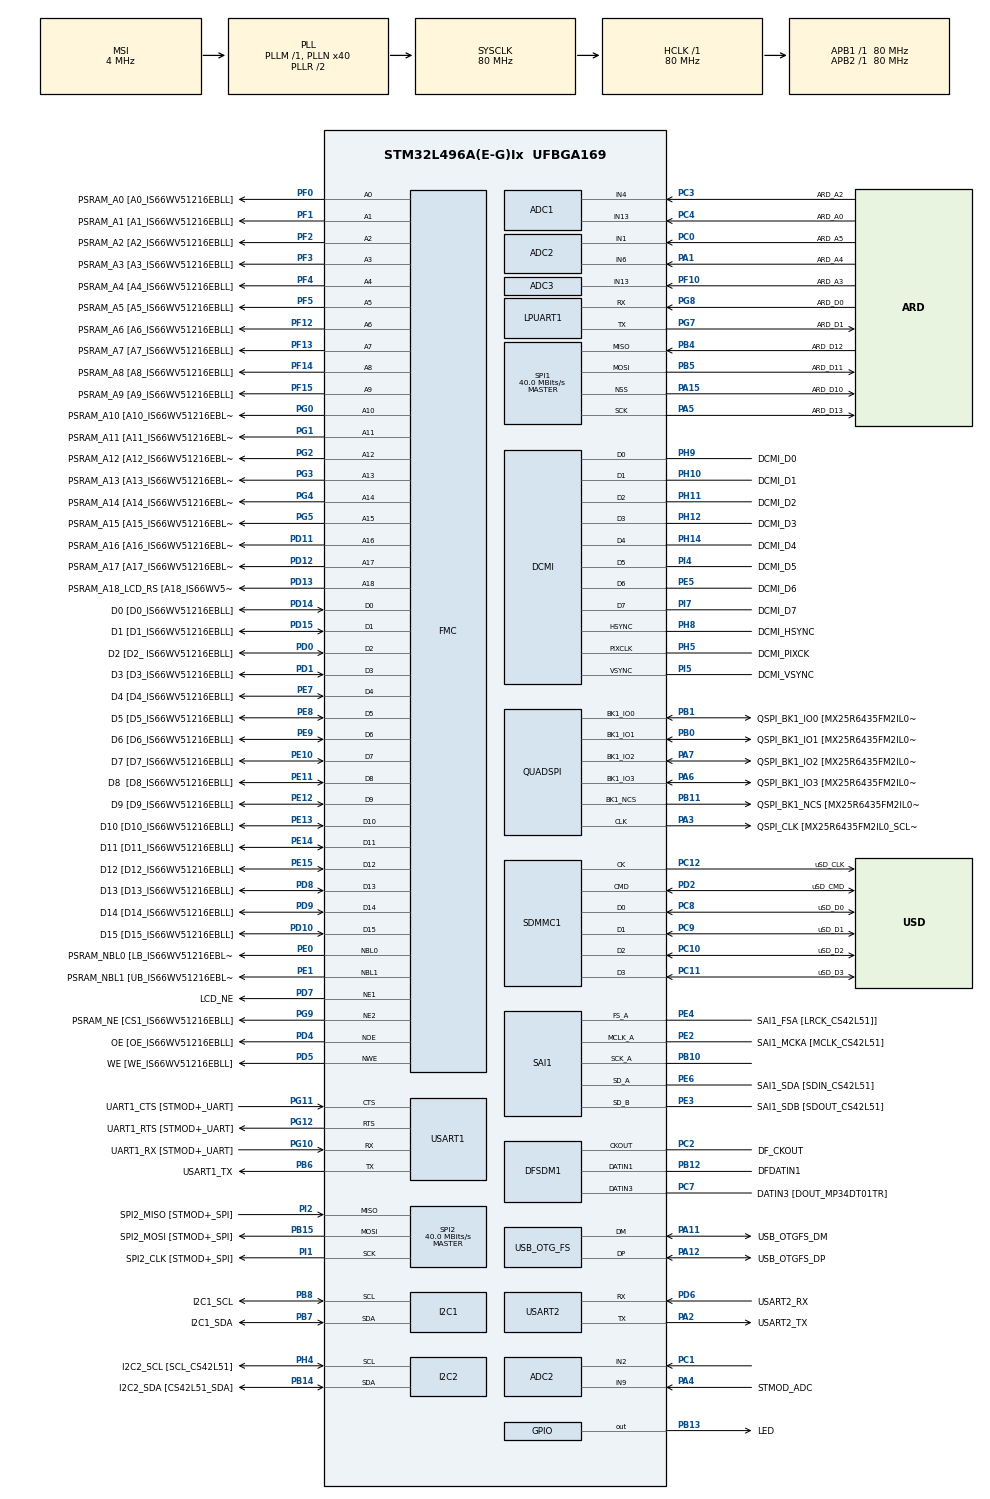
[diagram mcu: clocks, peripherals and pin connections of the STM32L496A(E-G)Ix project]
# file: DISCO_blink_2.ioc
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ADC1.Channel-0\#ChannelRegularConversion=ADC_CHANNEL_4
ADC1.ClockPrescaler=ADC_CLOCK_ASYNC_DIV4
ADC1.NbrOfConversionFlag=1
ADC1.OffsetNumber-0\#ChannelRegularConversion=ADC_OFFSET_NONE
ADC1.Rank-0\#ChannelRegularConversion=1
ADC1.SamplingTime-0\#ChannelRegularConversion=ADC_SAMPLETIME_2CYCLES_5
ADC1.master=1
ADC2.Channel-0\#ChannelRegularConversion=ADC_CHANNEL_9
ADC2.ClockPrescaler=ADC_CLOCK_ASYNC_DIV4
ADC2.NbrOfConversionFlag=1
ADC2.OffsetNumber-0\#ChannelRegularConversion=ADC_OFFSET_NONE
ADC2.Rank-0\#ChannelRegularConversion=1
ADC2.SamplingTime-0\#ChannelRegularConversion=ADC_SAMPLETIME_2CYCLES_5
ADC3.Channel-0\#ChannelRegularConversion=ADC_CHANNEL_13
ADC3.ClockPrescaler=ADC_CLOCK_ASYNC_DIV4
ADC3.NbrOfConversionFlag=1
ADC3.OffsetNumber-0\#ChannelRegularConversion=ADC_OFFSET_NONE
ADC3.Rank-0\#ChannelRegularConversion=1
ADC3.SamplingTime-0\#ChannelRegularConversion=ADC_SAMPLETIME_2CYCLES_5
DCMI.JPEGMode=DCMI_JPEG_DISABLE
I2C1.Timing=0x10D19CE4
I2C2.Timing=0x10D19CE4
Mcu.Family=STM32L4
Mcu.Name=STM32L496A(E-G)Ix
Mcu.Package=UFBGA169
NVIC.OTG_FS_IRQn=true\:0\:0\:false\:false\:true\:true\:true\:true
NVIC.PriorityGroup=NVIC_PRIORITYGROUP_4
PA0.GPIO_Label=STMOD_PWM
PA0.Mode=SYS_WakeUp0
PA0.Signal=SYS_WKUP1
PA1.GPIO_Label=ARD_A4
PA1.Signal=ADCx_IN6
PA10.GPIO_Label=USB_OTGFS_ID
PA10.Signal=USB_OTG_FS_ID
PA11.GPIO_Label=USB_OTGFS_DM
PA11.Mode=Device_Only
PA11.Signal=USB_OTG_FS_DM
PA12.GPIO_Label=USB_OTGFS_DP
PA12.Mode=Device_Only
PA12.Signal=USB_OTG_FS_DP
PA13\ (JTMS/SWDIO).GPIO_Label=SWDIO
PA13\ (JTMS/SWDIO).Mode=Serial_Wire
PA13\ (JTMS/SWDIO).Signal=SYS_JTMS-SWDIO
PA14\ (JTCK/SWCLK).GPIO_Label=SWCLK
PA14\ (JTCK/SWCLK).Mode=Serial_Wire
PA14\ (JTCK/SWCLK).Signal=SYS_JTCK-SWCLK
PA15\ (JTDI).GPIO_Label=ARD_D10
PA15\ (JTDI).Mode=NSS_Signal_Hard_Output
PA15\ (JTDI).Signal=SPI1_NSS
PA2.GPIO_Label=USART2_TX
PA2.Mode=Asynchronous
PA2.Signal=USART2_TX
PA3.GPIO_Label=QSPI_CLK [MX25R6435FM2IL0_SCLK]
PA3.Mode=Single Bank 1
PA3.Signal=QUADSPI_CLK
PA4.GPIO_Label=STMOD_ADC
PA4.Signal=ADCx_IN9
PA5.GPIO_Label=ARD_D13
PA5.Mode=Full_Duplex_Master
PA5.Signal=SPI1_SCK
PA6.GPIO_Label=QSPI_BK1_IO3 [MX25R6435FM2IL0_SIO3]
PA6.Mode=Single Bank 1
PA6.Signal=QUADSPI_BK1_IO3
PA7.GPIO_Label=QSPI_BK1_IO2 [MX25R6435FM2IL0_SIO2]
PA7.Mode=Single Bank 1
PA7.Signal=QUADSPI_BK1_IO2
PA8.GPIO_Label=DCMI_CLK
PA8.Signal=LPTIM2_OUT
PA9.GPIO_Label=USB_OTGFS_VBUS
PA9.Signal=USB_OTG_FS_VBUS
PB0.GPIO_Label=QSPI_BK1_IO1 [MX25R6435FM2IL0_SIO1]
PB0.Mode=Single Bank 1
PB0.Signal=QUADSPI_BK1_IO1
PB1.GPIO_Label=QSPI_BK1_IO0 [MX25R6435FM2IL0_SIO0]
PB1.Mode=Single Bank 1
PB1.Signal=QUADSPI_BK1_IO0
PB10.Mode=SAI_A_MasterWithClock
PB10.Signal=SAI1_SCK_A
PB11.GPIO_Label=QSPI_BK1_NCS [MX25R6435FM2IL0_CS]
PB11.Mode=Single Bank 1
PB11.Signal=QUADSPI_BK1_NCS
PB12.GPIO_Label=DFDATIN1
PB12.Signal=S_DATAIN1DFSDM1
PB13.GPIO_Label=LED
PB13.GPIO_ModeDefaultOutputPP=GPIO_MODE_OUTPUT_OD
PB13.GPIO_PuPd=GPIO_NOPULL
PB13.Signal=GPIO_Output
PB14.GPIO_Label=I2C2_SDA [CS42L51_SDA]
PB14.GPIO_Pu=GPIO_PULLUP
PB14.Mode=I2C
PB14.Signal=I2C2_SDA
PB15.GPIO_Label=SPI2_MOSI [STMOD+_SPI]
PB15.Mode=Full_Duplex_Master
PB15.Signal=SPI2_MOSI
PB3\ (JTDO/TRACESWO).GPIO_Label=SWO
PB3\ (JTDO/TRACESWO).Signal=SYS_JTDO-SWO
PB4\ (NJTRST).GPIO_Label=ARD_D12
PB4\ (NJTRST).Mode=Full_Duplex_Master
PB4\ (NJTRST).Signal=SPI1_MISO
PB5.GPIO_Label=ARD_D11
PB5.Mode=Full_Duplex_Master
PB5.Signal=SPI1_MOSI
PB6.GPIO_Label=USART1_TX
PB6.Mode=Asynchronous
PB6.Signal=USART1_TX
PB7.GPIO_Label=I2C1_SDA
PB7.GPIO_Pu=GPIO_PULLUP
PB7.Mode=I2C
PB7.Signal=I2C1_SDA
PB8.GPIO_Label=I2C1_SCL
PB8.GPIO_Pu=GPIO_PULLUP
PB8.Mode=I2C
PB8.Signal=I2C1_SCL
PB9.GPIO_Label=ARD_D5
PB9.Signal=S_TIM4_CH4
PC0.GPIO_Label=ARD_A5
PC0.Signal=ADCx_IN1
PC1.Signal=ADCx_IN2
PC10.GPIO_Label=uSD_D2
PC10.Mode=SD_4_bits_Wide_bus
PC10.Signal=SDMMC1_D2
PC11.GPIO_Label=uSD_D3
PC11.Mode=SD_4_bits_Wide_bus
PC11.Signal=SDMMC1_D3
PC12.GPIO_Label=uSD_CLK
PC12.Mode=SD_4_bits_Wide_bus
PC12.Signal=SDMMC1_CK
PC13.GPIO_Label=JOY_SEL [Selection_MT008]
PC13.Mode=SYS_WakeUp1
PC13.Signal=SYS_WKUP2
PC14-OSC32_IN\ (PC14).Mode=LSE-External-Oscillator
PC14-OSC32_IN\ (PC14).Signal=RCC_OSC32_IN
PC15-OSC32_OUT\ (PC15).Mode=LSE-External-Oscillator
PC15-OSC32_OUT\ (PC15).Signal=RCC_OSC32_OUT
PC2.GPIO_Label=DF_CKOUT
PC2.Signal=S_CKOUTDFSDM1
PC3.GPIO_Label=ARD_A2
PC3.Signal=ADCx_IN4
PC4.GPIO_Label=ARD_A0
PC4.Signal=ADCx_IN13
PC7.GPIO_Label=DATIN3 [DOUT_MP34DT01TR]
PC7.Signal=S_DATAIN3DFSDM1
PC8.GPIO_Label=uSD_D0
PC8.Mode=SD_4_bits_Wide_bus
PC8.Signal=SDMMC1_D0
PC9.GPIO_Label=uSD_D1
PC9.Mode=SD_4_bits_Wide_bus
PC9.Signal=SDMMC1_D1
PD0.GPIO_Label=D2 [D2_ IS66WV51216EBLL]
PD0.Signal=FMC_D2_DA2
PD1.GPIO_Label=D3 [D3_IS66WV51216EBLL]
PD1.Signal=FMC_D3_DA3
PD10.GPIO_Label=D15 [D15_IS66WV51216EBLL]
PD10.Signal=FMC_D15_DA15
PD11.GPIO_Label=PSRAM_A16 [A16_IS66WV51216EBLL]
PD11.Signal=FMC_A16_CLE
PD12.GPIO_Label=PSRAM_A17 [A17_IS66WV51216EBLL]
PD12.Signal=FMC_A17_ALE
PD13.GPIO_Label=PSRAM_A18_LCD_RS [A18_IS66WV51216EBLL]
PD13.Signal=FMC_A18
PD14.GPIO_Label=D0 [D0_IS66WV51216EBLL]
PD14.Signal=FMC_D0_DA0
PD15.GPIO_Label=D1 [D1_IS66WV51216EBLL]
PD15.Signal=FMC_D1_DA1
PD2.GPIO_Label=uSD_CMD
PD2.Mode=SD_4_bits_Wide_bus
PD2.Signal=SDMMC1_CMD
PD4.GPIO_Label=OE [OE_IS66WV51216EBLL]
PD4.Signal=FMC_NOE
PD5.GPIO_Label=WE [WE_IS66WV51216EBLL]
PD5.Signal=FMC_NWE
PD6.GPIO_Label=USART2_RX
PD6.Mode=Asynchronous
PD6.Signal=USART2_RX
PD7.GPIO_Label=LCD_NE
PD7.Mode=NorPsramChipSelect1_2
PD7.Signal=FMC_NE1
PD8.GPIO_Label=D13 [D13_IS66WV51216EBLL]
PD8.Signal=FMC_D13_DA13
PD9.GPIO_Label=D14 [D14_IS66WV51216EBLL]
PD9.Signal=FMC_D14_DA14
PE0.GPIO_Label=PSRAM_NBL0 [LB_IS66WV51216EBLL]
PE0.Signal=FMC_NBL0
PE1.GPIO_Label=PSRAM_NBL1 [UB_IS66WV51216EBLL]
PE1.Signal=FMC_NBL1
PE10.GPIO_Label=D7 [D7_IS66WV51216EBLL]
PE10.Signal=FMC_D7_DA7
PE11.GPIO_Label=D8  [D8_IS66WV51216EBLL]
PE11.Signal=FMC_D8_DA8
PE12.GPIO_Label=D9 [D9_IS66WV51216EBLL]
PE12.Signal=FMC_D9_DA9
PE13.GPIO_Label=D10 [D10_IS66WV51216EBLL]
PE13.Signal=FMC_D10_DA10
PE14.GPIO_Label=D11 [D11_IS66WV51216EBLL]
PE14.Signal=FMC_D11_DA11
PE15.GPIO_Label=D12 [D12_IS66WV51216EBLL]
PE15.Signal=FMC_D12_DA12
PE2.GPIO_Label=SAI1_MCKA [MCLK_CS42L51]
PE2.Mode=SAI_A_MasterWithClock
PE2.Signal=SAI1_MCLK_A
PE3.GPIO_Label=SAI1_SDB [SDOUT_CS42L51]
PE3.Mode=SAI_B_SyncSlave
PE3.Signal=SAI1_SD_B
PE4.GPIO_Label=SAI1_FSA [LRCK_CS42L51]]
PE4.Mode=SAI_A_MasterWithClock
PE4.Signal=SAI1_FS_A
PE5.GPIO_Label=DCMI_D6
PE5.Mode=Slave_8_bits_External_Synchro
PE5.Signal=DCMI_D6
PE6.GPIO_Label=SAI1_SDA [SDIN_CS42L51]
PE6.Mode=SAI_A_MasterWithClock
PE6.Signal=SAI1_SD_A
PE7.GPIO_Label=D4 [D4_IS66WV51216EBLL]
PE7.Signal=FMC_D4_DA4
PE8.GPIO_Label=D5 [D5_IS66WV51216EBLL]
PE8.Signal=FMC_D5_DA5
PE9.GPIO_Label=D6 [D6_IS66WV51216EBLL]
PE9.Signal=FMC_D6_DA6
PF0.GPIO_Label=PSRAM_A0 [A0_IS66WV51216EBLL]
PF0.Signal=FMC_A0
PF1.GPIO_Label=PSRAM_A1 [A1_IS66WV51216EBLL]
PF1.Signal=FMC_A1
PF10.GPIO_Label=ARD_A3
PF10.Mode=IN13-Single-Ended
PF10.Signal=ADC3_IN13
PF12.GPIO_Label=PSRAM_A6 [A6_IS66WV51216EBLL]
PF12.Signal=FMC_A6
PF13.GPIO_Label=PSRAM_A7 [A7_IS66WV51216EBLL]
PF13.Signal=FMC_A7
PF14.GPIO_Label=PSRAM_A8 [A8_IS66WV51216EBLL]
PF14.Signal=FMC_A8
PF15.GPIO_Label=PSRAM_A9 [A9_IS66WV51216EBLL]
PF15.Signal=FMC_A9
PF2.GPIO_Label=PSRAM_A2 [A2_IS66WV51216EBLL]
PF2.Signal=FMC_A2
PF3.GPIO_Label=PSRAM_A3 [A3_IS66WV51216EBLL]
PF3.Signal=FMC_A3
PF4.GPIO_Label=PSRAM_A4 [A4_IS66WV51216EBLL]
PF4.Signal=FMC_A4
PF5.GPIO_Label=PSRAM_A5 [A5_IS66WV51216EBLL]
PF5.Signal=FMC_A5
PG0.GPIO_Label=PSRAM_A10 [A10_IS66WV51216EBLL]
PG0.Signal=FMC_A10
PG1.GPIO_Label=PSRAM_A11 [A11_IS66WV51216EBLL]
PG1.Signal=FMC_A11
PG10.GPIO_Label=UART1_RX [STMOD+_UART]
PG10.Mode=Asynchronous
PG10.Signal=USART1_RX
PG11.GPIO_Label=UART1_CTS [STMOD+_UART]
PG11.Mode=CTS_RTS
PG11.Signal=USART1_CTS
PG12.GPIO_Label=UART1_RTS [STMOD+_UART]
PG12.Mode=CTS_RTS
PG12.Signal=USART1_RTS
PG2.GPIO_Label=PSRAM_A12 [A12_IS66WV51216EBLL]
PG2.Signal=FMC_A12
PG3.GPIO_Label=PSRAM_A13 [A13_IS66WV51216EBLL]
PG3.Signal=FMC_A13
PG4.GPIO_Label=PSRAM_A14 [A14_IS66WV51216EBLL]
PG4.Signal=FMC_A14
PG5.GPIO_Label=PSRAM_A15 [A15_IS66WV51216EBLL]
PG5.Signal=FMC_A15
PG7.GPIO_Label=ARD_D1
PG7.Mode=Asynchronous
PG7.Signal=LPUART1_TX
PG8.GPIO_Label=ARD_D0
PG8.Mode=Asynchronous
PG8.Signal=LPUART1_RX
PG9.GPIO_Label=PSRAM_NE [CS1_IS66WV51216EBLL]
PG9.Mode=NorPsramChipSelect2_1
PG9.Signal=FMC_NE2
PH0-OSC_IN\ (PH0).Mode=HSE-External-Oscillator
PH0-OSC_IN\ (PH0).Signal=RCC_OSC_IN
PH1-OSC_OUT\ (PH1).Mode=HSE-External-Oscillator
PH1-OSC_OUT\ (PH1).Signal=RCC_OSC_OUT
PH10.GPIO_Label=DCMI_D1
PH10.Mode=Slave_8_bits_External_Synchro
PH10.Signal=DCMI_D1
PH11.GPIO_Label=DCMI_D2
PH11.Mode=Slave_8_bits_External_Synchro
PH11.Signal=DCMI_D2
PH12.GPIO_Label=DCMI_D3
PH12.Mode=Slave_8_bits_External_Synchro
PH12.Signal=DCMI_D3
PH13.GPIO_Label=ARD_D9
PH13.Signal=TIM8_CH1N
PH14.GPIO_Label=DCMI_D4
PH14.Mode=Slave_8_bits_External_Synchro
PH14.Signal=DCMI_D4
PH15.GPIO_Label=ARD_D3
PH15.Signal=TIM8_CH3N
PH4.GPIO_Label=I2C2_SCL [SCL_CS42L51]
PH4.GPIO_Pu=GPIO_PULLUP
PH4.Mode=I2C
PH4.Signal=I2C2_SCL
PH5.GPIO_Label=DCMI_PIXCK
PH5.Mode=Slave_8_bits_External_Synchro
PH5.Signal=DCMI_PIXCLK
PH8.GPIO_Label=DCMI_HSYNC
PH8.Mode=Slave_8_bits_External_Synchro
PH8.Signal=DCMI_HSYNC
PH9.GPIO_Label=DCMI_D0
PH9.Mode=Slave_8_bits_External_Synchro
PH9.Signal=DCMI_D0
PI1.GPIO_Label=SPI2_CLK [STMOD+_SPI]
PI1.Mode=Full_Duplex_Master
PI1.Signal=SPI2_SCK
PI2.GPIO_Label=SPI2_MISO [STMOD+_SPI]
PI2.Mode=Full_Duplex_Master
PI2.Signal=SPI2_MISO
PI4.GPIO_Label=DCMI_D5
PI4.Mode=Slave_8_bits_External_Synchro
PI4.Signal=DCMI_D5
PI5.GPIO_Label=DCMI_VSYNC
PI5.Mode=Slave_8_bits_External_Synchro
PI5.Signal=DCMI_VSYNC
PI6.GPIO_Label=ARD_D6
PI6.Signal=S_TIM8_CH2
PI7.GPIO_Label=DCMI_D7
PI7.Mode=Slave_8_bits_External_Synchro
PI7.Signal=DCMI_D7
ProjectManager.HeapSize=0x200
ProjectManager.StackSize=0x400
ProjectManager.TargetToolchain=STM32CubeIDE
QUADSPI.ClockPrescaler=2
QUADSPI.FifoThreshold=4
QUADSPI.FlashSize=23
QUADSPI.SampleShifting=QSPI_SAMPLE_SHIFTING_HALFCYCLE
RCC.ADCFreq_Value=48000000
RCC.AHBFreq_Value=80000000
RCC.APB1Freq_Value=80000000
RCC.APB1TimFreq_Value=80000000
RCC.APB2Freq_Value=80000000
RCC.APB2TimFreq_Value=80000000
RCC.CortexFreq_Value=80000000
RCC.FLatency-AdvancedSettings=FLASH_LATENCY_4
RCC.HCLKFreq_Value=80000000
RCC.HSI48_VALUE=48000000
RCC.HSI_VALUE=16000000
RCC.MSI_VALUE=4000000
RCC.PLLN=40
RCC.PLLSAI1N=24
RCC.RTCClockSelection=RCC_RTCCLKSOURCE_LSE
RCC.SYSCLKFreq_VALUE=80000000
RCC.SYSCLKSource=RCC_SYSCLKSOURCE_PLLCLK
RCC.USBFreq_Value=48000000
RCC.VCOOutputFreq_Value=160000000
SAI1.ErrorAudioFreq-SAI_A_MasterWithClock=-2.34 %
SAI1.Instance-SAI_A_MasterWithClock=SAI$Index_Block_A
SAI1.Instance-SAI_B_SyncSlave=SAI$Index_Block_B
SAI1.MClockEnable-SAI_A_MasterWithClock=SAI_MASTERCLOCK_ENABLE
SAI1.RealAudioFreq-SAI_A_MasterWithClock=187.5 KHz
SAI1.VirtualMode-SAI_A_MasterWithClock=VM_MASTER
SAI1.VirtualMode-SAI_B_SyncSlave=VM_SLAVE
SH.ADCx_IN1.0=ADC2_IN1,IN1-Single-Ended
SH.ADCx_IN13.0=ADC1_IN13,IN13-Single-Ended
SH.ADCx_IN2.0=ADC2_IN2,IN2-Single-Ended
SH.ADCx_IN4.0=ADC1_IN4,IN4-Single-Ended
SH.ADCx_IN6.0=ADC2_IN6,IN6-Single-Ended
SH.ADCx_IN9.0=ADC2_IN9,IN9-Single-Ended
SH.FMC_A0.0=FMC_A0,18b-a1
SH.FMC_A1.0=FMC_A1,18b-a1
SH.FMC_A10.0=FMC_A10,18b-a1
SH.FMC_A11.0=FMC_A11,18b-a1
SH.FMC_A12.0=FMC_A12,18b-a1
SH.FMC_A13.0=FMC_A13,18b-a1
SH.FMC_A14.0=FMC_A14,18b-a1
SH.FMC_A15.0=FMC_A15,18b-a1
SH.FMC_A16_CLE.0=FMC_A16,18b-a1
SH.FMC_A17_ALE.0=FMC_A17,18b-a1
SH.FMC_A18.0=FMC_A18,A18_2
SH.FMC_A2.0=FMC_A2,18b-a1
SH.FMC_A3.0=FMC_A3,18b-a1
SH.FMC_A4.0=FMC_A4,18b-a1
SH.FMC_A5.0=FMC_A5,18b-a1
SH.FMC_A6.0=FMC_A6,18b-a1
SH.FMC_A7.0=FMC_A7,18b-a1
SH.FMC_A8.0=FMC_A8,18b-a1
SH.FMC_A9.0=FMC_A9,18b-a1
SH.FMC_D0_DA0.0=FMC_D0,16b-d1
SH.FMC_D0_DA0.1=FMC_D0,16b-d2
SH.FMC_D10_DA10.0=FMC_D10,16b-d1
SH.FMC_D10_DA10.1=FMC_D10,16b-d2
SH.FMC_D11_DA11.0=FMC_D11,16b-d1
SH.FMC_D11_DA11.1=FMC_D11,16b-d2
SH.FMC_D12_DA12.0=FMC_D12,16b-d1
SH.FMC_D12_DA12.1=FMC_D12,16b-d2
SH.FMC_D13_DA13.0=FMC_D13,16b-d1
SH.FMC_D13_DA13.1=FMC_D13,16b-d2
SH.FMC_D14_DA14.0=FMC_D14,16b-d1
SH.FMC_D14_DA14.1=FMC_D14,16b-d2
SH.FMC_D15_DA15.0=FMC_D15,16b-d1
SH.FMC_D15_DA15.1=FMC_D15,16b-d2
SH.FMC_D1_DA1.0=FMC_D1,16b-d1
SH.FMC_D1_DA1.1=FMC_D1,16b-d2
SH.FMC_D2_DA2.0=FMC_D2,16b-d1
SH.FMC_D2_DA2.1=FMC_D2,16b-d2
SH.FMC_D3_DA3.0=FMC_D3,16b-d1
SH.FMC_D3_DA3.1=FMC_D3,16b-d2
SH.FMC_D4_DA4.0=FMC_D4,16b-d1
SH.FMC_D4_DA4.1=FMC_D4,16b-d2
SH.FMC_D5_DA5.0=FMC_D5,16b-d1
SH.FMC_D5_DA5.1=FMC_D5,16b-d2
SH.FMC_D6_DA6.0=FMC_D6,16b-d1
SH.FMC_D6_DA6.1=FMC_D6,16b-d2
SH.FMC_D7_DA7.0=FMC_D7,16b-d1
SH.FMC_D7_DA7.1=FMC_D7,16b-d2
SH.FMC_D8_DA8.0=FMC_D8,16b-d1
SH.FMC_D8_DA8.1=FMC_D8,16b-d2
SH.FMC_D9_DA9.0=FMC_D9,16b-d1
SH.FMC_D9_DA9.1=FMC_D9,16b-d2
SH.FMC_NBL0.0=FMC_NBL0,2ByteEnable1
SH.FMC_NBL1.0=FMC_NBL1,2ByteEnable1
SH.FMC_NOE.0=FMC_NOE,Sram1
SH.FMC_NOE.1=FMC_NOE,Lcd2
SH.FMC_NWE.0=FMC_NWE,Sram1
SH.FMC_NWE.1=FMC_NWE,Lcd2
SH.S_CKOUTDFSDM1.0=DFSDM1_CKOUT,PDM_SPI_Input_from_ch23_and_Internal_Clock
SH.S_CKOUTDFSDM1.1=DFSDM1_CKOUT,PDM_SPI_input_from_ch1_and_internal_clock
SH.S_DATAIN1DFSDM1.0=DFSDM1_DATIN1,PDM_SPI_input_from_ch1_and_internal_clock
SH.S_DATAIN3DFSDM1.0=DFSDM1_DATIN3,PDM_SPI_Input_from_ch23_and_Internal_Clock
SH.S_TIM4_CH4.0=TIM4_CH4
SH.S_TIM8_CH2.0=TIM8_CH2
SPI1.BaudRatePrescaler=SPI_BAUDRATEPRESCALER_2
SPI1.CalculateBaudRate=40.0 MBits/s
SPI1.Direction=SPI_DIRECTION_2LINES
SPI1.Mode=SPI_MODE_MASTER
SPI1.VirtualNSS=VM_NSSHARD
SPI1.VirtualType=VM_MASTER
SPI2.BaudRatePrescaler=SPI_BAUDRATEPRESCALER_2
SPI2.CalculateBaudRate=40.0 MBits/s
SPI2.Direction=SPI_DIRECTION_2LINES
SPI2.Mode=SPI_MODE_MASTER
SPI2.VirtualType=VM_MASTER
USART1.VirtualMode-Asynchronous=VM_ASYNC
USART2.VirtualMode-Asynchronous=VM_ASYNC
USB_DEVICE.CLASS_NAME_FS=CDC
USB_DEVICE.VirtualMode=Cdc
USB_DEVICE.VirtualModeFS=Cdc_FS
USB_OTG_FS.VirtualMode=Device_Only
VP_RTC_VS_RTC_Activate.Mode=RTC_Enabled
VP_RTC_VS_RTC_Calendar.Mode=RTC_Calendar
VP_USB_DEVICE_VS_USB_DEVICE_CDC_FS.Mode=CDC_FS
board=STM32L496G-DISCO

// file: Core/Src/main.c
/* USER CODE BEGIN Header */
/**
  ******************************************************************************
  * @file           : main.c
  * @brief          : Main program body
  ******************************************************************************
  * @attention
  *
  * Copyright (c) 2025 STMicroelectronics.
  * All rights reserved.
  *
  * This software is licensed under terms that can be found in the LICENSE file
  * in the root directory of this software component.
  * If no LICENSE file comes with this software, it is provided AS-IS.
  *
  ******************************************************************************
  */
/* USER CODE END Header */
#include "main.h"
#include "usb_device.h"

ADC_HandleTypeDef hadc1;
ADC_HandleTypeDef hadc2;
ADC_HandleTypeDef hadc3;

DCMI_HandleTypeDef hdcmi;

DFSDM_Channel_HandleTypeDef hdfsdm1_channel1;
DFSDM_Channel_HandleTypeDef hdfsdm1_channel2;

I2C_HandleTypeDef hi2c1;
I2C_HandleTypeDef hi2c2;

UART_HandleTypeDef hlpuart1;
UART_HandleTypeDef huart1;
UART_HandleTypeDef huart2;

QSPI_HandleTypeDef hqspi;

RTC_HandleTypeDef hrtc;

SAI_HandleTypeDef hsai_BlockA1;
SAI_HandleTypeDef hsai_BlockB1;

SD_HandleTypeDef hsd1;

SPI_HandleTypeDef hspi1;
SPI_HandleTypeDef hspi2;

SRAM_HandleTypeDef hsram1;
SRAM_HandleTypeDef hsram2;

void SystemClock_Config(void);
void PeriphCommonClock_Config(void);
static void MX_GPIO_Init(void);
static void MX_ADC1_Init(void);
static void MX_ADC2_Init(void);
static void MX_ADC3_Init(void);
static void MX_DCMI_Init(void);
static void MX_DFSDM1_Init(void);
static void MX_FMC_Init(void);
static void MX_I2C1_Init(void);
static void MX_I2C2_Init(void);
static void MX_LPUART1_UART_Init(void);
static void MX_USART1_UART_Init(void);
static void MX_USART2_UART_Init(void);
static void MX_QUADSPI_Init(void);
static void MX_SAI1_Init(void);
static void MX_SDMMC1_SD_Init(void);
static void MX_SPI1_Init(void);
static void MX_SPI2_Init(void);
static void MX_RTC_Init(void);

int main(void)
{

  /* MCU Configuration--------------------------------------------------------*/

  /* Reset of all peripherals, Initializes the Flash interface and the Systick. */
  HAL_Init();

  /* Configure the system clock */
  SystemClock_Config();

  /* Configure the peripherals common clocks */
  PeriphCommonClock_Config();

  /* Initialize all configured peripherals */
  MX_GPIO_Init();
  MX_ADC1_Init();
  MX_ADC2_Init();
  MX_ADC3_Init();
  MX_DCMI_Init();
  MX_DFSDM1_Init();
  MX_FMC_Init();
  MX_I2C1_Init();
  MX_I2C2_Init();
  MX_LPUART1_UART_Init();
  MX_USART1_UART_Init();
  MX_USART2_UART_Init();
  MX_QUADSPI_Init();
  MX_SAI1_Init();
  MX_SDMMC1_SD_Init();
  MX_SPI1_Init();
  MX_SPI2_Init();
  MX_USB_DEVICE_Init();
  MX_RTC_Init();

  /* Infinite loop */
  /* USER CODE BEGIN WHILE */
  while (1)
  {
	  HAL_GPIO_TogglePin(LED_GPIO_Port, LED_Pin);
	  HAL_Delay(100);
    /* USER CODE END WHILE */

  }
}

void SystemClock_Config(void)
{
  RCC_OscInitTypeDef RCC_OscInitStruct = {0};
  RCC_ClkInitTypeDef RCC_ClkInitStruct = {0};

  /** Configure the main internal regulator output voltage
  */
  if (HAL_PWREx_ControlVoltageScaling(PWR_REGULATOR_VOLTAGE_SCALE1) != HAL_OK)
  {
    Error_Handler();
  }

  /** Configure LSE Drive Capability
  */
  HAL_PWR_EnableBkUpAccess();
  __HAL_RCC_LSEDRIVE_CONFIG(RCC_LSEDRIVE_LOW);

  /** Initializes the RCC Oscillators according to the specified parameters
  * in the RCC_OscInitTypeDef structure.
  */
  RCC_OscInitStruct.OscillatorType = RCC_OSCILLATORTYPE_LSE|RCC_OSCILLATORTYPE_MSI;
  RCC_OscInitStruct.LSEState = RCC_LSE_ON;
  RCC_OscInitStruct.MSIState = RCC_MSI_ON;
  RCC_OscInitStruct.MSICalibrationValue = 0;
  RCC_OscInitStruct.MSIClockRange = RCC_MSIRANGE_6;
  RCC_OscInitStruct.PLL.PLLState = RCC_PLL_ON;
  RCC_OscInitStruct.PLL.PLLSource = RCC_PLLSOURCE_MSI;
  RCC_OscInitStruct.PLL.PLLM = 1;
  RCC_OscInitStruct.PLL.PLLN = 40;
  RCC_OscInitStruct.PLL.PLLP = RCC_PLLP_DIV2;
  RCC_OscInitStruct.PLL.PLLQ = RCC_PLLQ_DIV2;
  RCC_OscInitStruct.PLL.PLLR = RCC_PLLR_DIV2;
  if (HAL_RCC_OscConfig(&RCC_OscInitStruct) != HAL_OK)
  {
    Error_Handler();
  }

  /** Initializes the CPU, AHB and APB buses clocks
  */
  RCC_ClkInitStruct.ClockType = RCC_CLOCKTYPE_HCLK|RCC_CLOCKTYPE_SYSCLK
                              |RCC_CLOCKTYPE_PCLK1|RCC_CLOCKTYPE_PCLK2;
  RCC_ClkInitStruct.SYSCLKSource = RCC_SYSCLKSOURCE_PLLCLK;
  RCC_ClkInitStruct.AHBCLKDivider = RCC_SYSCLK_DIV1;
  RCC_ClkInitStruct.APB1CLKDivider = RCC_HCLK_DIV1;
  RCC_ClkInitStruct.APB2CLKDivider = RCC_HCLK_DIV1;

  if (HAL_RCC_ClockConfig(&RCC_ClkInitStruct, FLASH_LATENCY_4) != HAL_OK)
  {
    Error_Handler();
  }

  /** Enable MSI Auto calibration
  */
  HAL_RCCEx_EnableMSIPLLMode();
}

void PeriphCommonClock_Config(void)
{
  RCC_PeriphCLKInitTypeDef PeriphClkInit = {0};

  /** Initializes the peripherals clock
  */
  PeriphClkInit.PeriphClockSelection = RCC_PERIPHCLK_SAI1|RCC_PERIPHCLK_USB
                              |RCC_PERIPHCLK_SDMMC1|RCC_PERIPHCLK_ADC;
  PeriphClkInit.Sai1ClockSelection = RCC_SAI1CLKSOURCE_PLLSAI1;
  PeriphClkInit.AdcClockSelection = RCC_ADCCLKSOURCE_PLLSAI1;
  PeriphClkInit.UsbClockSelection = RCC_USBCLKSOURCE_PLLSAI1;
  PeriphClkInit.Sdmmc1ClockSelection = RCC_SDMMC1CLKSOURCE_PLLSAI1;
  PeriphClkInit.PLLSAI1.PLLSAI1Source = RCC_PLLSOURCE_MSI;
  PeriphClkInit.PLLSAI1.PLLSAI1M = 1;
  PeriphClkInit.PLLSAI1.PLLSAI1N = 24;
  PeriphClkInit.PLLSAI1.PLLSAI1P = RCC_PLLP_DIV2;
  PeriphClkInit.PLLSAI1.PLLSAI1Q = RCC_PLLQ_DIV2;
  PeriphClkInit.PLLSAI1.PLLSAI1R = RCC_PLLR_DIV2;
  PeriphClkInit.PLLSAI1.PLLSAI1ClockOut = RCC_PLLSAI1_SAI1CLK|RCC_PLLSAI1_48M2CLK
                              |RCC_PLLSAI1_ADC1CLK;
  if (HAL_RCCEx_PeriphCLKConfig(&PeriphClkInit) != HAL_OK)
  {
    Error_Handler();
  }
}

static void MX_ADC1_Init(void)
{

  ADC_MultiModeTypeDef multimode = {0};
  ADC_ChannelConfTypeDef sConfig = {0};

  /** Common config
  */
  hadc1.Instance = ADC1;
  hadc1.Init.ClockPrescaler = ADC_CLOCK_ASYNC_DIV4;
  hadc1.Init.Resolution = ADC_RESOLUTION_12B;
  hadc1.Init.DataAlign = ADC_DATAALIGN_RIGHT;
  hadc1.Init.ScanConvMode = ADC_SCAN_DISABLE;
  hadc1.Init.EOCSelection = ADC_EOC_SINGLE_CONV;
  hadc1.Init.LowPowerAutoWait = DISABLE;
  hadc1.Init.ContinuousConvMode = DISABLE;
  hadc1.Init.NbrOfConversion = 1;
  hadc1.Init.DiscontinuousConvMode = DISABLE;
  hadc1.Init.ExternalTrigConv = ADC_SOFTWARE_START;
  hadc1.Init.ExternalTrigConvEdge = ADC_EXTERNALTRIGCONVEDGE_NONE;
  hadc1.Init.DMAContinuousRequests = DISABLE;
  hadc1.Init.Overrun = ADC_OVR_DATA_PRESERVED;
  hadc1.Init.OversamplingMode = DISABLE;
  if (HAL_ADC_Init(&hadc1) != HAL_OK)
  {
    Error_Handler();
  }

  /** Configure the ADC multi-mode
  */
  multimode.Mode = ADC_MODE_INDEPENDENT;
  if (HAL_ADCEx_MultiModeConfigChannel(&hadc1, &multimode) != HAL_OK)
  {
    Error_Handler();
  }

  /** Configure Regular Channel
  */
  sConfig.Channel = ADC_CHANNEL_4;
  sConfig.Rank = ADC_REGULAR_RANK_1;
  sConfig.SamplingTime = ADC_SAMPLETIME_2CYCLES_5;
  sConfig.SingleDiff = ADC_SINGLE_ENDED;
  sConfig.OffsetNumber = ADC_OFFSET_NONE;
  sConfig.Offset = 0;
  if (HAL_ADC_ConfigChannel(&hadc1, &sConfig) != HAL_OK)
  {
    Error_Handler();
  }

}

static void MX_ADC2_Init(void)
{

  ADC_ChannelConfTypeDef sConfig = {0};

  /** Common config
  */
  hadc2.Instance = ADC2;
  hadc2.Init.ClockPrescaler = ADC_CLOCK_ASYNC_DIV4;
  hadc2.Init.Resolution = ADC_RESOLUTION_12B;
  hadc2.Init.DataAlign = ADC_DATAALIGN_RIGHT;
  hadc2.Init.ScanConvMode = ADC_SCAN_DISABLE;
  hadc2.Init.EOCSelection = ADC_EOC_SINGLE_CONV;
  hadc2.Init.LowPowerAutoWait = DISABLE;
  hadc2.Init.ContinuousConvMode = DISABLE;
  hadc2.Init.NbrOfConversion = 1;
  hadc2.Init.DiscontinuousConvMode = DISABLE;
  hadc2.Init.ExternalTrigConv = ADC_SOFTWARE_START;
  hadc2.Init.ExternalTrigConvEdge = ADC_EXTERNALTRIGCONVEDGE_NONE;
  hadc2.Init.DMAContinuousRequests = DISABLE;
  hadc2.Init.Overrun = ADC_OVR_DATA_PRESERVED;
  hadc2.Init.OversamplingMode = DISABLE;
  if (HAL_ADC_Init(&hadc2) != HAL_OK)
  {
    Error_Handler();
  }

  /** Configure Regular Channel
  */
  sConfig.Channel = ADC_CHANNEL_9;
  sConfig.Rank = ADC_REGULAR_RANK_1;
  sConfig.SamplingTime = ADC_SAMPLETIME_2CYCLES_5;
  sConfig.SingleDiff = ADC_SINGLE_ENDED;
  sConfig.OffsetNumber = ADC_OFFSET_NONE;
  sConfig.Offset = 0;
  if (HAL_ADC_ConfigChannel(&hadc2, &sConfig) != HAL_OK)
  {
    Error_Handler();
  }

}

static void MX_ADC3_Init(void)
{

  ADC_ChannelConfTypeDef sConfig = {0};

  /** Common config
  */
  hadc3.Instance = ADC3;
  hadc3.Init.ClockPrescaler = ADC_CLOCK_ASYNC_DIV4;
  hadc3.Init.Resolution = ADC_RESOLUTION_12B;
  hadc3.Init.DataAlign = ADC_DATAALIGN_RIGHT;
  hadc3.Init.ScanConvMode = ADC_SCAN_DISABLE;
  hadc3.Init.EOCSelection = ADC_EOC_SINGLE_CONV;
  hadc3.Init.LowPowerAutoWait = DISABLE;
  hadc3.Init.ContinuousConvMode = DISABLE;
  hadc3.Init.NbrOfConversion = 1;
  hadc3.Init.DiscontinuousConvMode = DISABLE;
  hadc3.Init.ExternalTrigConv = ADC_SOFTWARE_START;
  hadc3.Init.ExternalTrigConvEdge = ADC_EXTERNALTRIGCONVEDGE_NONE;
  hadc3.Init.DMAContinuousRequests = DISABLE;
  hadc3.Init.Overrun = ADC_OVR_DATA_PRESERVED;
  hadc3.Init.OversamplingMode = DISABLE;
  if (HAL_ADC_Init(&hadc3) != HAL_OK)
  {
    Error_Handler();
  }

  /** Configure Regular Channel
  */
  sConfig.Channel = ADC_CHANNEL_13;
  sConfig.Rank = ADC_REGULAR_RANK_1;
  sConfig.SamplingTime = ADC_SAMPLETIME_2CYCLES_5;
  sConfig.SingleDiff = ADC_SINGLE_ENDED;
  sConfig.OffsetNumber = ADC_OFFSET_NONE;
  sConfig.Offset = 0;
  if (HAL_ADC_ConfigChannel(&hadc3, &sConfig) != HAL_OK)
  {
    Error_Handler();
  }

}

static void MX_DCMI_Init(void)
{

  hdcmi.Instance = DCMI;
  hdcmi.Init.SynchroMode = DCMI_SYNCHRO_HARDWARE;
  hdcmi.Init.PCKPolarity = DCMI_PCKPOLARITY_FALLING;
  hdcmi.Init.VSPolarity = DCMI_VSPOLARITY_LOW;
  hdcmi.Init.HSPolarity = DCMI_HSPOLARITY_LOW;
  hdcmi.Init.CaptureRate = DCMI_CR_ALL_FRAME;
  hdcmi.Init.ExtendedDataMode = DCMI_EXTEND_DATA_8B;
  hdcmi.Init.JPEGMode = DCMI_JPEG_DISABLE;
  hdcmi.Init.ByteSelectMode = DCMI_BSM_ALL;
  hdcmi.Init.ByteSelectStart = DCMI_OEBS_ODD;
  hdcmi.Init.LineSelectMode = DCMI_LSM_ALL;
  hdcmi.Init.LineSelectStart = DCMI_OELS_ODD;
  if (HAL_DCMI_Init(&hdcmi) != HAL_OK)
  {
    Error_Handler();
  }

}

static void MX_DFSDM1_Init(void)
{

  hdfsdm1_channel1.Instance = DFSDM1_Channel1;
  hdfsdm1_channel1.Init.OutputClock.Activation = ENABLE;
  hdfsdm1_channel1.Init.OutputClock.Selection = DFSDM_CHANNEL_OUTPUT_CLOCK_SYSTEM;
  hdfsdm1_channel1.Init.OutputClock.Divider = 2;
  hdfsdm1_channel1.Init.Input.Multiplexer = DFSDM_CHANNEL_EXTERNAL_INPUTS;
  hdfsdm1_channel1.Init.Input.DataPacking = DFSDM_CHANNEL_STANDARD_MODE;
  hdfsdm1_channel1.Init.Input.Pins = DFSDM_CHANNEL_SAME_CHANNEL_PINS;
  hdfsdm1_channel1.Init.SerialInterface.Type = DFSDM_CHANNEL_SPI_RISING;
  hdfsdm1_channel1.Init.SerialInterface.SpiClock = DFSDM_CHANNEL_SPI_CLOCK_INTERNAL;
  hdfsdm1_channel1.Init.Awd.FilterOrder = DFSDM_CHANNEL_FASTSINC_ORDER;
  hdfsdm1_channel1.Init.Awd.Oversampling = 1;
  hdfsdm1_channel1.Init.Offset = 0;
  hdfsdm1_channel1.Init.RightBitShift = 0x00;
  if (HAL_DFSDM_ChannelInit(&hdfsdm1_channel1) != HAL_OK)
  {
    Error_Handler();
  }
  hdfsdm1_channel2.Instance = DFSDM1_Channel2;
  hdfsdm1_channel2.Init.OutputClock.Activation = ENABLE;
  hdfsdm1_channel2.Init.OutputClock.Selection = DFSDM_CHANNEL_OUTPUT_CLOCK_SYSTEM;
  hdfsdm1_channel2.Init.OutputClock.Divider = 2;
  hdfsdm1_channel2.Init.Input.Multiplexer = DFSDM_CHANNEL_EXTERNAL_INPUTS;
  hdfsdm1_channel2.Init.Input.DataPacking = DFSDM_CHANNEL_STANDARD_MODE;
  hdfsdm1_channel2.Init.Input.Pins = DFSDM_CHANNEL_FOLLOWING_CHANNEL_PINS;
  hdfsdm1_channel2.Init.SerialInterface.Type = DFSDM_CHANNEL_SPI_RISING;
  hdfsdm1_channel2.Init.SerialInterface.SpiClock = DFSDM_CHANNEL_SPI_CLOCK_INTERNAL;
  hdfsdm1_channel2.Init.Awd.FilterOrder = DFSDM_CHANNEL_FASTSINC_ORDER;
  hdfsdm1_channel2.Init.Awd.Oversampling = 1;
  hdfsdm1_channel2.Init.Offset = 0;
  hdfsdm1_channel2.Init.RightBitShift = 0x00;
  if (HAL_DFSDM_ChannelInit(&hdfsdm1_channel2) != HAL_OK)
  {
    Error_Handler();
  }

}

static void MX_I2C1_Init(void)
{

  hi2c1.Instance = I2C1;
  hi2c1.Init.Timing = 0x10D19CE4;
  hi2c1.Init.OwnAddress1 = 0;
  hi2c1.Init.AddressingMode = I2C_ADDRESSINGMODE_7BIT;
  hi2c1.Init.DualAddressMode = I2C_DUALADDRESS_DISABLE;
  hi2c1.Init.OwnAddress2 = 0;
  hi2c1.Init.OwnAddress2Masks = I2C_OA2_NOMASK;
  hi2c1.Init.GeneralCallMode = I2C_GENERALCALL_DISABLE;
  hi2c1.Init.NoStretchMode = I2C_NOSTRETCH_DISABLE;
  if (HAL_I2C_Init(&hi2c1) != HAL_OK)
  {
    Error_Handler();
  }

  /** Configure Analogue filter
  */
  if (HAL_I2CEx_ConfigAnalogFilter(&hi2c1, I2C_ANALOGFILTER_ENABLE) != HAL_OK)
  {
    Error_Handler();
  }

  /** Configure Digital filter
  */
  if (HAL_I2CEx_ConfigDigitalFilter(&hi2c1, 0) != HAL_OK)
  {
    Error_Handler();
  }

}

static void MX_I2C2_Init(void)
{

  hi2c2.Instance = I2C2;
  hi2c2.Init.Timing = 0x10D19CE4;
  hi2c2.Init.OwnAddress1 = 0;
  hi2c2.Init.AddressingMode = I2C_ADDRESSINGMODE_7BIT;
  hi2c2.Init.DualAddressMode = I2C_DUALADDRESS_DISABLE;
  hi2c2.Init.OwnAddress2 = 0;
  hi2c2.Init.OwnAddress2Masks = I2C_OA2_NOMASK;
  hi2c2.Init.GeneralCallMode = I2C_GENERALCALL_DISABLE;
  hi2c2.Init.NoStretchMode = I2C_NOSTRETCH_DISABLE;
  if (HAL_I2C_Init(&hi2c2) != HAL_OK)
  {
    Error_Handler();
  }

  /** Configure Analogue filter
  */
  if (HAL_I2CEx_ConfigAnalogFilter(&hi2c2, I2C_ANALOGFILTER_ENABLE) != HAL_OK)
  {
    Error_Handler();
  }

  /** Configure Digital filter
  */
  if (HAL_I2CEx_ConfigDigitalFilter(&hi2c2, 0) != HAL_OK)
  {
    Error_Handler();
  }

}

static void MX_LPUART1_UART_Init(void)
{

  hlpuart1.Instance = LPUART1;
  hlpuart1.Init.BaudRate = 209700;
  hlpuart1.Init.WordLength = UART_WORDLENGTH_7B;
  hlpuart1.Init.StopBits = UART_STOPBITS_1;
  hlpuart1.Init.Parity = UART_PARITY_NONE;
  hlpuart1.Init.Mode = UART_MODE_TX_RX;
  hlpuart1.Init.HwFlowCtl = UART_HWCONTROL_NONE;
  hlpuart1.Init.OneBitSampling = UART_ONE_BIT_SAMPLE_DISABLE;
  hlpuart1.AdvancedInit.AdvFeatureInit = UART_ADVFEATURE_NO_INIT;
  if (HAL_UART_Init(&hlpuart1) != HAL_OK)
  {
    Error_Handler();
  }

}

static void MX_USART1_UART_Init(void)
{

  huart1.Instance = USART1;
  huart1.Init.BaudRate = 115200;
  huart1.Init.WordLength = UART_WORDLENGTH_8B;
  huart1.Init.StopBits = UART_STOPBITS_1;
  huart1.Init.Parity = UART_PARITY_NONE;
  huart1.Init.Mode = UART_MODE_TX_RX;
  huart1.Init.HwFlowCtl = UART_HWCONTROL_RTS_CTS;
  huart1.Init.OverSampling = UART_OVERSAMPLING_16;
  huart1.Init.OneBitSampling = UART_ONE_BIT_SAMPLE_DISABLE;
  huart1.AdvancedInit.AdvFeatureInit = UART_ADVFEATURE_NO_INIT;
  if (HAL_UART_Init(&huart1) != HAL_OK)
  {
    Error_Handler();
  }

}

static void MX_USART2_UART_Init(void)
{

  huart2.Instance = USART2;
  huart2.Init.BaudRate = 115200;
  huart2.Init.WordLength = UART_WORDLENGTH_8B;
  huart2.Init.StopBits = UART_STOPBITS_1;
  huart2.Init.Parity = UART_PARITY_NONE;
  huart2.Init.Mode = UART_MODE_TX_RX;
  huart2.Init.HwFlowCtl = UART_HWCONTROL_NONE;
  huart2.Init.OverSampling = UART_OVERSAMPLING_16;
  huart2.Init.OneBitSampling = UART_ONE_BIT_SAMPLE_DISABLE;
  huart2.AdvancedInit.AdvFeatureInit = UART_ADVFEATURE_NO_INIT;
  if (HAL_UART_Init(&huart2) != HAL_OK)
  {
    Error_Handler();
  }

}

static void MX_QUADSPI_Init(void)
{

  /* QUADSPI parameter configuration*/
  hqspi.Instance = QUADSPI;
  hqspi.Init.ClockPrescaler = 2;
  hqspi.Init.FifoThreshold = 4;
  hqspi.Init.SampleShifting = QSPI_SAMPLE_SHIFTING_HALFCYCLE;
  hqspi.Init.FlashSize = 23;
  hqspi.Init.ChipSelectHighTime = QSPI_CS_HIGH_TIME_1_CYCLE;
  hqspi.Init.ClockMode = QSPI_CLOCK_MODE_0;
  hqspi.Init.FlashID = QSPI_FLASH_ID_1;
  hqspi.Init.DualFlash = QSPI_DUALFLASH_DISABLE;
  if (HAL_QSPI_Init(&hqspi) != HAL_OK)
  {
    Error_Handler();
  }

}

static void MX_RTC_Init(void)
{

  RTC_TimeTypeDef sTime = {0};
  RTC_DateTypeDef sDate = {0};

  /** Initialize RTC Only
  */
  hrtc.Instance = RTC;
  hrtc.Init.HourFormat = RTC_HOURFORMAT_24;
  hrtc.Init.AsynchPrediv = 127;
  hrtc.Init.SynchPrediv = 255;
  hrtc.Init.OutPut = RTC_OUTPUT_DISABLE;
  hrtc.Init.OutPutRemap = RTC_OUTPUT_REMAP_NONE;
  hrtc.Init.OutPutPolarity = RTC_OUTPUT_POLARITY_HIGH;
  hrtc.Init.OutPutType = RTC_OUTPUT_TYPE_OPENDRAIN;
  if (HAL_RTC_Init(&hrtc) != HAL_OK)
  {
    Error_Handler();
  }

  /** Initialize RTC and set the Time and Date
  */
  sTime.Hours = 0x0;
  sTime.Minutes = 0x0;
  sTime.Seconds = 0x0;
  sTime.DayLightSaving = RTC_DAYLIGHTSAVING_NONE;
  sTime.StoreOperation = RTC_STOREOPERATION_RESET;
  if (HAL_RTC_SetTime(&hrtc, &sTime, RTC_FORMAT_BCD) != HAL_OK)
  {
    Error_Handler();
  }
  sDate.WeekDay = RTC_WEEKDAY_MONDAY;
  sDate.Month = RTC_MONTH_JANUARY;
  sDate.Date = 0x1;
  sDate.Year = 0x0;

  if (HAL_RTC_SetDate(&hrtc, &sDate, RTC_FORMAT_BCD) != HAL_OK)
  {
    Error_Handler();
  }

}

static void MX_SAI1_Init(void)
{

  hsai_BlockA1.Instance = SAI1_Block_A;
  hsai_BlockA1.Init.Protocol = SAI_FREE_PROTOCOL;
  hsai_BlockA1.Init.AudioMode = SAI_MODEMASTER_TX;
  hsai_BlockA1.Init.DataSize = SAI_DATASIZE_8;
  hsai_BlockA1.Init.FirstBit = SAI_FIRSTBIT_MSB;
  hsai_BlockA1.Init.ClockStrobing = SAI_CLOCKSTROBING_FALLINGEDGE;
  hsai_BlockA1.Init.Synchro = SAI_ASYNCHRONOUS;
  hsai_BlockA1.Init.OutputDrive = SAI_OUTPUTDRIVE_DISABLE;
  hsai_BlockA1.Init.NoDivider = SAI_MASTERDIVIDER_ENABLE;
  hsai_BlockA1.Init.FIFOThreshold = SAI_FIFOTHRESHOLD_EMPTY;
  hsai_BlockA1.Init.AudioFrequency = SAI_AUDIO_FREQUENCY_192K;
  hsai_BlockA1.Init.SynchroExt = SAI_SYNCEXT_DISABLE;
  hsai_BlockA1.Init.MonoStereoMode = SAI_STEREOMODE;
  hsai_BlockA1.Init.CompandingMode = SAI_NOCOMPANDING;
  hsai_BlockA1.Init.TriState = SAI_OUTPUT_NOTRELEASED;
  hsai_BlockA1.FrameInit.FrameLength = 8;
  hsai_BlockA1.FrameInit.ActiveFrameLength = 1;
  hsai_BlockA1.FrameInit.FSDefinition = SAI_FS_STARTFRAME;
  hsai_BlockA1.FrameInit.FSPolarity = SAI_FS_ACTIVE_LOW;
  hsai_BlockA1.FrameInit.FSOffset = SAI_FS_FIRSTBIT;
  hsai_BlockA1.SlotInit.FirstBitOffset = 0;
  hsai_BlockA1.SlotInit.SlotSize = SAI_SLOTSIZE_DATASIZE;
  hsai_BlockA1.SlotInit.SlotNumber = 1;
  hsai_BlockA1.SlotInit.SlotActive = 0x00000000;
  if (HAL_SAI_Init(&hsai_BlockA1) != HAL_OK)
  {
    Error_Handler();
  }
  hsai_BlockB1.Instance = SAI1_Block_B;
  hsai_BlockB1.Init.Protocol = SAI_FREE_PROTOCOL;
  hsai_BlockB1.Init.AudioMode = SAI_MODESLAVE_RX;
  hsai_BlockB1.Init.DataSize = SAI_DATASIZE_8;
  hsai_BlockB1.Init.FirstBit = SAI_FIRSTBIT_MSB;
  hsai_BlockB1.Init.ClockStrobing = SAI_CLOCKSTROBING_FALLINGEDGE;
  hsai_BlockB1.Init.Synchro = SAI_SYNCHRONOUS;
  hsai_BlockB1.Init.OutputDrive = SAI_OUTPUTDRIVE_DISABLE;
  hsai_BlockB1.Init.FIFOThreshold = SAI_FIFOTHRESHOLD_EMPTY;
  hsai_BlockB1.Init.SynchroExt = SAI_SYNCEXT_DISABLE;
  hsai_BlockB1.Init.MonoStereoMode = SAI_STEREOMODE;
  hsai_BlockB1.Init.CompandingMode = SAI_NOCOMPANDING;
  hsai_BlockB1.Init.TriState = SAI_OUTPUT_NOTRELEASED;
  hsai_BlockB1.FrameInit.FrameLength = 8;
  hsai_BlockB1.FrameInit.ActiveFrameLength = 1;
  hsai_BlockB1.FrameInit.FSDefinition = SAI_FS_STARTFRAME;
  hsai_BlockB1.FrameInit.FSPolarity = SAI_FS_ACTIVE_LOW;
  hsai_BlockB1.FrameInit.FSOffset = SAI_FS_FIRSTBIT;
  hsai_BlockB1.SlotInit.FirstBitOffset = 0;
  hsai_BlockB1.SlotInit.SlotSize = SAI_SLOTSIZE_DATASIZE;
  hsai_BlockB1.SlotInit.SlotNumber = 1;
  hsai_BlockB1.SlotInit.SlotActive = 0x00000000;
  if (HAL_SAI_Init(&hsai_BlockB1) != HAL_OK)
  {
    Error_Handler();
  }

}

static void MX_SDMMC1_SD_Init(void)
{

  hsd1.Instance = SDMMC1;
  hsd1.Init.ClockEdge = SDMMC_CLOCK_EDGE_RISING;
  hsd1.Init.ClockBypass = SDMMC_CLOCK_BYPASS_DISABLE;
  hsd1.Init.ClockPowerSave = SDMMC_CLOCK_POWER_SAVE_DISABLE;
  hsd1.Init.BusWide = SDMMC_BUS_WIDE_4B;
  hsd1.Init.HardwareFlowControl = SDMMC_HARDWARE_FLOW_CONTROL_DISABLE;
  hsd1.Init.ClockDiv = 0;
  if (HAL_SD_Init(&hsd1) != HAL_OK)
  {
    Error_Handler();
  }
  if (HAL_SD_ConfigWideBusOperation(&hsd1, SDMMC_BUS_WIDE_4B) != HAL_OK)
  {
    Error_Handler();
  }

}

static void MX_SPI1_Init(void)
{

  /* SPI1 parameter configuration*/
  hspi1.Instance = SPI1;
  hspi1.Init.Mode = SPI_MODE_MASTER;
  hspi1.Init.Direction = SPI_DIRECTION_2LINES;
  hspi1.Init.DataSize = SPI_DATASIZE_4BIT;
  hspi1.Init.CLKPolarity = SPI_POLARITY_LOW;
  hspi1.Init.CLKPhase = SPI_PHASE_1EDGE;
  hspi1.Init.NSS = SPI_NSS_HARD_OUTPUT;
  hspi1.Init.BaudRatePrescaler = SPI_BAUDRATEPRESCALER_2;
  hspi1.Init.FirstBit = SPI_FIRSTBIT_MSB;
  hspi1.Init.TIMode = SPI_TIMODE_DISABLE;
  hspi1.Init.CRCCalculation = SPI_CRCCALCULATION_DISABLE;
  hspi1.Init.CRCPolynomial = 7;
  hspi1.Init.CRCLength = SPI_CRC_LENGTH_DATASIZE;
  hspi1.Init.NSSPMode = SPI_NSS_PULSE_ENABLE;
  if (HAL_SPI_Init(&hspi1) != HAL_OK)
  {
    Error_Handler();
  }

}

static void MX_SPI2_Init(void)
{

  /* SPI2 parameter configuration*/
  hspi2.Instance = SPI2;
  hspi2.Init.Mode = SPI_MODE_MASTER;
  hspi2.Init.Direction = SPI_DIRECTION_2LINES;
  hspi2.Init.DataSize = SPI_DATASIZE_4BIT;
  hspi2.Init.CLKPolarity = SPI_POLARITY_LOW;
  hspi2.Init.CLKPhase = SPI_PHASE_1EDGE;
  hspi2.Init.NSS = SPI_NSS_SOFT;
  hspi2.Init.BaudRatePrescaler = SPI_BAUDRATEPRESCALER_2;
  hspi2.Init.FirstBit = SPI_FIRSTBIT_MSB;
  hspi2.Init.TIMode = SPI_TIMODE_DISABLE;
  hspi2.Init.CRCCalculation = SPI_CRCCALCULATION_DISABLE;
  hspi2.Init.CRCPolynomial = 7;
  hspi2.Init.CRCLength = SPI_CRC_LENGTH_DATASIZE;
  hspi2.Init.NSSPMode = SPI_NSS_PULSE_ENABLE;
  if (HAL_SPI_Init(&hspi2) != HAL_OK)
  {
    Error_Handler();
  }

}

/* FMC initialization function */
static void MX_FMC_Init(void)
{

  FMC_NORSRAM_TimingTypeDef Timing = {0};

  /** Perform the SRAM1 memory initialization sequence
  */
  hsram1.Instance = FMC_NORSRAM_DEVICE;
  hsram1.Extended = FMC_NORSRAM_EXTENDED_DEVICE;
  /* hsram1.Init */
  hsram1.Init.NSBank = FMC_NORSRAM_BANK2;
  hsram1.Init.DataAddressMux = FMC_DATA_ADDRESS_MUX_DISABLE;
  hsram1.Init.MemoryType = FMC_MEMORY_TYPE_SRAM;
  hsram1.Init.MemoryDataWidth = FMC_NORSRAM_MEM_BUS_WIDTH_16;
  hsram1.Init.BurstAccessMode = FMC_BURST_ACCESS_MODE_DISABLE;
  hsram1.Init.WaitSignalPolarity = FMC_WAIT_SIGNAL_POLARITY_LOW;
  hsram1.Init.WaitSignalActive = FMC_WAIT_TIMING_BEFORE_WS;
  hsram1.Init.WriteOperation = FMC_WRITE_OPERATION_DISABLE;
  hsram1.Init.WaitSignal = FMC_WAIT_SIGNAL_DISABLE;
  hsram1.Init.ExtendedMode = FMC_EXTENDED_MODE_DISABLE;
  hsram1.Init.AsynchronousWait = FMC_ASYNCHRONOUS_WAIT_DISABLE;
  hsram1.Init.WriteBurst = FMC_WRITE_BURST_DISABLE;
  hsram1.Init.ContinuousClock = FMC_CONTINUOUS_CLOCK_SYNC_ONLY;
  hsram1.Init.WriteFifo = FMC_WRITE_FIFO_ENABLE;
  hsram1.Init.PageSize = FMC_PAGE_SIZE_NONE;
  /* Timing */
  Timing.AddressSetupTime = 15;
  Timing.AddressHoldTime = 15;
  Timing.DataSetupTime = 255;
  Timing.BusTurnAroundDuration = 15;
  Timing.CLKDivision = 16;
  Timing.DataLatency = 17;
  Timing.AccessMode = FMC_ACCESS_MODE_A;
  /* ExtTiming */

  if (HAL_SRAM_Init(&hsram1, &Timing, NULL) != HAL_OK)
  {
    Error_Handler( );
  }

  /** Perform the SRAM2 memory initialization sequence
  */
  hsram2.Instance = FMC_NORSRAM_DEVICE;
  hsram2.Extended = FMC_NORSRAM_EXTENDED_DEVICE;
  /* hsram2.Init */
  hsram2.Init.NSBank = FMC_NORSRAM_BANK1;
  hsram2.Init.DataAddressMux = FMC_DATA_ADDRESS_MUX_DISABLE;
  hsram2.Init.MemoryType = FMC_MEMORY_TYPE_SRAM;
  hsram2.Init.MemoryDataWidth = FMC_NORSRAM_MEM_BUS_WIDTH_16;
  hsram2.Init.BurstAccessMode = FMC_BURST_ACCESS_MODE_DISABLE;
  hsram2.Init.WaitSignalPolarity = FMC_WAIT_SIGNAL_POLARITY_LOW;
  hsram2.Init.WaitSignalActive = FMC_WAIT_TIMING_BEFORE_WS;
  hsram2.Init.WriteOperation = FMC_WRITE_OPERATION_ENABLE;
  hsram2.Init.WaitSignal = FMC_WAIT_SIGNAL_DISABLE;
  hsram2.Init.ExtendedMode = FMC_EXTENDED_MODE_DISABLE;
  hsram2.Init.AsynchronousWait = FMC_ASYNCHRONOUS_WAIT_DISABLE;
  hsram2.Init.WriteBurst = FMC_WRITE_BURST_DISABLE;
  hsram2.Init.ContinuousClock = FMC_CONTINUOUS_CLOCK_SYNC_ONLY;
  hsram2.Init.WriteFifo = FMC_WRITE_FIFO_ENABLE;
  hsram2.Init.PageSize = FMC_PAGE_SIZE_NONE;
  /* Timing */
  Timing.AddressSetupTime = 15;
  Timing.AddressHoldTime = 15;
  Timing.DataSetupTime = 255;
  Timing.BusTurnAroundDuration = 15;
  Timing.CLKDivision = 16;
  Timing.DataLatency = 17;
  Timing.AccessMode = FMC_ACCESS_MODE_A;
  /* ExtTiming */

  if (HAL_SRAM_Init(&hsram2, &Timing, NULL) != HAL_OK)
  {
    Error_Handler( );
  }

}

static void MX_GPIO_Init(void)
{
  GPIO_InitTypeDef GPIO_InitStruct = {0};

  /* GPIO Ports Clock Enable */
  __HAL_RCC_GPIOE_CLK_ENABLE();
  __HAL_RCC_GPIOB_CLK_ENABLE();
  __HAL_RCC_GPIOA_CLK_ENABLE();
  __HAL_RCC_GPIOH_CLK_ENABLE();
  __HAL_RCC_GPIOI_CLK_ENABLE();
  __HAL_RCC_GPIOG_CLK_ENABLE();
  HAL_PWREx_EnableVddIO2();
  __HAL_RCC_GPIOD_CLK_ENABLE();
  __HAL_RCC_GPIOC_CLK_ENABLE();
  __HAL_RCC_GPIOF_CLK_ENABLE();

  /*Configure GPIO pin Output Level */
  HAL_GPIO_WritePin(LED_GPIO_Port, LED_Pin, GPIO_PIN_RESET);

  /*Configure GPIO pin : ARD_D6_Pin */
  GPIO_InitStruct.Pin = ARD_D6_Pin;
  GPIO_InitStruct.Mode = GPIO_MODE_AF_PP;
  GPIO_InitStruct.Pull = GPIO_NOPULL;
  GPIO_InitStruct.Speed = GPIO_SPEED_FREQ_LOW;
  GPIO_InitStruct.Alternate = GPIO_AF3_TIM8;
  HAL_GPIO_Init(ARD_D6_GPIO_Port, &GPIO_InitStruct);

  /*Configure GPIO pins : ARD_D3_Pin ARD_D9_Pin */
  GPIO_InitStruct.Pin = ARD_D3_Pin|ARD_D9_Pin;
  GPIO_InitStruct.Mode = GPIO_MODE_AF_PP;
  GPIO_InitStruct.Pull = GPIO_NOPULL;
  GPIO_InitStruct.Speed = GPIO_SPEED_FREQ_LOW;
  GPIO_InitStruct.Alternate = GPIO_AF3_TIM8;
  HAL_GPIO_Init(GPIOH, &GPIO_InitStruct);

  /*Configure GPIO pin : ARD_D5_Pin */
  GPIO_InitStruct.Pin = ARD_D5_Pin;
  GPIO_InitStruct.Mode = GPIO_MODE_AF_PP;
  GPIO_InitStruct.Pull = GPIO_NOPULL;
  GPIO_InitStruct.Speed = GPIO_SPEED_FREQ_LOW;
  GPIO_InitStruct.Alternate = GPIO_AF2_TIM4;
  HAL_GPIO_Init(ARD_D5_GPIO_Port, &GPIO_InitStruct);

  /*Configure GPIO pin : DCMI_CLK_Pin */
  GPIO_InitStruct.Pin = DCMI_CLK_Pin;
  GPIO_InitStruct.Mode = GPIO_MODE_AF_PP;
  GPIO_InitStruct.Pull = GPIO_NOPULL;
  GPIO_InitStruct.Speed = GPIO_SPEED_FREQ_LOW;
  GPIO_InitStruct.Alternate = GPIO_AF14_LPTIM2;
  HAL_GPIO_Init(DCMI_CLK_GPIO_Port, &GPIO_InitStruct);

  /*Configure GPIO pin : LED_Pin */
  GPIO_InitStruct.Pin = LED_Pin;
  GPIO_InitStruct.Mode = GPIO_MODE_OUTPUT_OD;
  GPIO_InitStruct.Pull = GPIO_NOPULL;
  GPIO_InitStruct.Speed = GPIO_SPEED_FREQ_LOW;
  HAL_GPIO_Init(LED_GPIO_Port, &GPIO_InitStruct);

}

void Error_Handler(void)
{
  __disable_irq();
  while (1)
  {
  }
}
